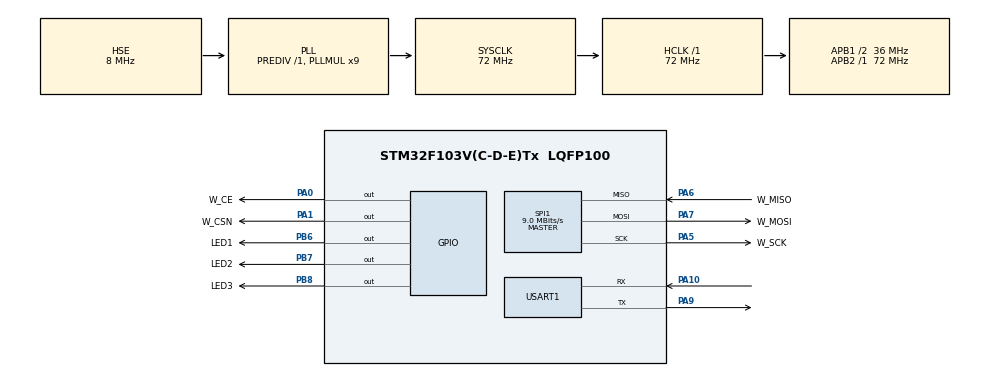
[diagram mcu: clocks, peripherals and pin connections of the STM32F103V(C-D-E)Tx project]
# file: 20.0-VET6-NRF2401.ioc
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Mcu.Family=STM32F1
Mcu.Name=STM32F103V(C-D-E)Tx
Mcu.Package=LQFP100
NVIC.PriorityGroup=NVIC_PRIORITYGROUP_4
OSC_IN.Mode=HSE-External-Oscillator
OSC_IN.Signal=RCC_OSC_IN
OSC_OUT.Mode=HSE-External-Oscillator
OSC_OUT.Signal=RCC_OSC_OUT
PA0-WKUP.GPIO_Label=W_CE
PA0-WKUP.GPIO_Speed=GPIO_SPEED_FREQ_MEDIUM
PA0-WKUP.Signal=GPIO_Output
PA1.GPIO_Label=W_CSN
PA1.GPIO_Speed=GPIO_SPEED_FREQ_MEDIUM
PA1.PinState=GPIO_PIN_SET
PA1.Signal=GPIO_Output
PA1.Stacked=true
PA10.Mode=Asynchronous
PA10.Signal=USART1_RX
PA5.GPIO_Label=W_SCK
PA5.Mode=Full_Duplex_Master
PA5.Signal=SPI1_SCK
PA6.GPIO_Label=W_MISO
PA6.Mode=Full_Duplex_Master
PA6.Signal=SPI1_MISO
PA7.GPIO_Label=W_MOSI
PA7.Mode=Full_Duplex_Master
PA7.Signal=SPI1_MOSI
PA9.Mode=Asynchronous
PA9.Signal=USART1_TX
PB6.GPIO_Label=LED1
PB6.GPIO_Speed=GPIO_SPEED_FREQ_MEDIUM
PB6.Signal=GPIO_Output
PB7.GPIO_Label=LED2
PB7.GPIO_Speed=GPIO_SPEED_FREQ_MEDIUM
PB7.Signal=GPIO_Output
PB8.GPIO_Label=LED3
PB8.GPIO_Speed=GPIO_SPEED_FREQ_MEDIUM
PB8.Signal=GPIO_Output
ProjectManager.HeapSize=0x200
ProjectManager.StackSize=0x400
ProjectManager.TargetToolchain=CMake
RCC.AHBFreq_Value=72000000
RCC.APB1CLKDivider=RCC_HCLK_DIV2
RCC.APB1Freq_Value=36000000
RCC.APB1TimFreq_Value=72000000
RCC.APB2Freq_Value=72000000
RCC.APB2TimFreq_Value=72000000
RCC.HCLKFreq_Value=72000000
RCC.PLLMUL=RCC_PLL_MUL9
RCC.PLLSourceVirtual=RCC_PLLSOURCE_HSE
RCC.SYSCLKFreq_VALUE=72000000
RCC.SYSCLKSource=RCC_SYSCLKSOURCE_PLLCLK
RCC.USBFreq_Value=72000000
SPI1.BaudRatePrescaler=SPI_BAUDRATEPRESCALER_8
SPI1.CalculateBaudRate=9.0 MBits/s
SPI1.Direction=SPI_DIRECTION_2LINES
SPI1.FirstBit=SPI_FIRSTBIT_MSB
SPI1.Mode=SPI_MODE_MASTER
SPI1.VirtualType=VM_MASTER
USART1.VirtualMode=VM_ASYNC
VP_SYS_VS_ND.Mode=No_Debug
board=custom

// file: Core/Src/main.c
/* USER CODE BEGIN Header */
/**
 ******************************************************************************
 * @file           : main.c
 * @brief          : Main program body
 ******************************************************************************
 * @attention
 *
 * Copyright (c) 2026 STMicroelectronics.
 * All rights reserved.
 *
 * This software is licensed under terms that can be found in the LICENSE file
 * in the root directory of this software component.
 * If no LICENSE file comes with this software, it is provided AS-IS.
 *
 ******************************************************************************
 */
/* USER CODE END Header */
#include "main.h"
#include "spi.h"
#include "usart.h"
#include "gpio.h"

/* USER CODE BEGIN Includes */
#include <string.h>
#include <stdio.h>
#include "nrf24l01.h"
/* USER CODE END Includes */

void SystemClock_Config(void);

int main(void)
{

  /* MCU Configuration--------------------------------------------------------*/

  /* Reset of all peripherals, Initializes the Flash interface and the Systick. */
  HAL_Init();

  /* Configure the system clock */
  SystemClock_Config();

  /* Initialize all configured peripherals */
  MX_GPIO_Init();
  MX_USART1_UART_Init();
  MX_SPI1_Init();
  /* USER CODE BEGIN 2 */
  uint8_t tx[5] = {0, 1, 2, 3, 4};
  uint8_t rx[5] ;
  memset(rx, 0xff, sizeof(rx));
  NRF24L01_WriteReg(NRF24L01_TX_ADDR, tx, 5);
  NRF24L01_ReadReg(NRF24L01_TX_ADDR, rx, 5);
  char str[100];

  sprintf(str, "%02X %02X %02X %02X %02X\n",
          rx[0], rx[1], rx[2], rx[3], rx[4]);
  /* USER CODE END 2 */

  /* Infinite loop */
  while (1)
  {

    /* USER CODE BEGIN 3 */
    HAL_UART_Transmit(&huart1, (const __uint8_t *)str, strlen(str), 100);
    HAL_Delay(1000);
  }
  /* USER CODE END 3 */
}

void SystemClock_Config(void)
{
  RCC_OscInitTypeDef RCC_OscInitStruct = {0};
  RCC_ClkInitTypeDef RCC_ClkInitStruct = {0};

  /** Initializes the RCC Oscillators according to the specified parameters
   * in the RCC_OscInitTypeDef structure.
   */
  RCC_OscInitStruct.OscillatorType = RCC_OSCILLATORTYPE_HSE;
  RCC_OscInitStruct.HSEState = RCC_HSE_ON;
  RCC_OscInitStruct.HSEPredivValue = RCC_HSE_PREDIV_DIV1;
  RCC_OscInitStruct.HSIState = RCC_HSI_ON;
  RCC_OscInitStruct.PLL.PLLState = RCC_PLL_ON;
  RCC_OscInitStruct.PLL.PLLSource = RCC_PLLSOURCE_HSE;
  RCC_OscInitStruct.PLL.PLLMUL = RCC_PLL_MUL9;
  if (HAL_RCC_OscConfig(&RCC_OscInitStruct) != HAL_OK)
  {
    Error_Handler();
  }

  /** Initializes the CPU, AHB and APB buses clocks
   */
  RCC_ClkInitStruct.ClockType = RCC_CLOCKTYPE_HCLK | RCC_CLOCKTYPE_SYSCLK | RCC_CLOCKTYPE_PCLK1 | RCC_CLOCKTYPE_PCLK2;
  RCC_ClkInitStruct.SYSCLKSource = RCC_SYSCLKSOURCE_PLLCLK;
  RCC_ClkInitStruct.AHBCLKDivider = RCC_SYSCLK_DIV1;
  RCC_ClkInitStruct.APB1CLKDivider = RCC_HCLK_DIV2;
  RCC_ClkInitStruct.APB2CLKDivider = RCC_HCLK_DIV1;

  if (HAL_RCC_ClockConfig(&RCC_ClkInitStruct, FLASH_LATENCY_2) != HAL_OK)
  {
    Error_Handler();
  }
}

void Error_Handler(void)
{
  __disable_irq();
  while (1)
  {
  }
}
